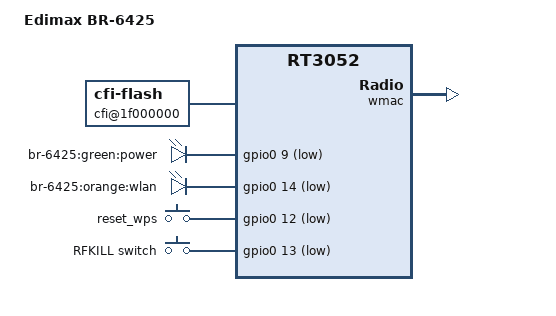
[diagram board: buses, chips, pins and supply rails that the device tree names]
/dts-v1/;

#include "rt3050.dtsi"

/ {
	compatible = "BR-6425", "ralink,rt3052-soc";
	model = "Edimax BR-6425";

	cfi@1f000000 {
		compatible = "cfi-flash";
		reg = <0x1f000000 0x800000>;
		bank-width = <2>;
		device-width = <2>;
		#address-cells = <1>;
		#size-cells = <1>;
	};

	gpio-leds {
		compatible = "gpio-leds";

		power {
			label = "br-6425:green:power";
			gpios = <&gpio0 9 1>;
		};

		wlan {
			label = "br-6425:orange:wlan";
			gpios = <&gpio0 14 1>;
		};
	};

	gpio-keys-polled {
		compatible = "gpio-keys-polled";
		#address-cells = <1>;
		#size-cells = <0>;
		poll-interval = <20>;

		reset_wps {
			label = "reset_wps";
			gpios = <&gpio0 12 1>;
			linux,code = <0x198>;
		};

		rfkill {
			label = "RFKILL switch";
			gpios = <&gpio0 13 1>;
			linux,code = <0xf7>;
		};
	};
};

&pinctrl {
	state_default: pinctrl0 {
		gpio {
			ralink,group = "spi", "i2c", "jtag", "rgmii", "mdio", "uartf";
			ralink,function = "gpio";
		};
	};
};

&ethernet {
/*	mtd-mac-address = <&factory 0x4>; */
};

&esw {
	mediatek,portmap = <0x2f>;
};

&wmac {
/*	ralink,mtd-eeprom = <&factory 0>; */
};
